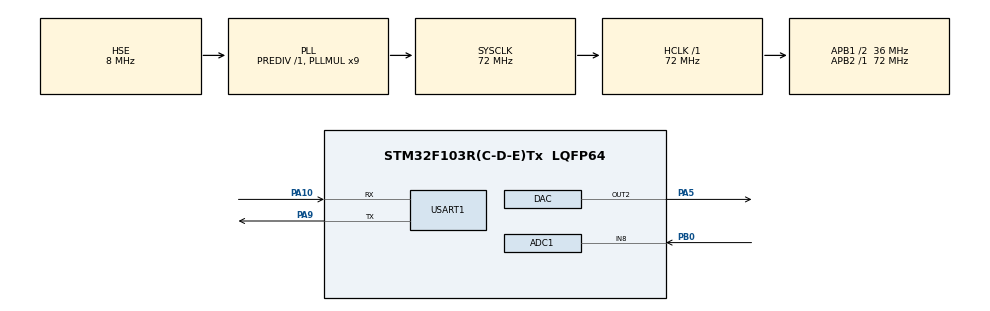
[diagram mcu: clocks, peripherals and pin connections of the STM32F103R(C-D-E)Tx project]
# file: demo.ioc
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ADC1.Channel-0\#ChannelRegularConversion=ADC_CHANNEL_8
ADC1.ContinuousConvMode=DISABLE
ADC1.NbrOfConversionFlag=1
ADC1.Rank-0\#ChannelRegularConversion=1
ADC1.SamplingTime-0\#ChannelRegularConversion=ADC_SAMPLETIME_55CYCLES_5
ADC1.master=1
DAC.DAC_Trigger2=DAC_TRIGGER_T2_TRGO
DAC.TriangleAmplitude2=DAC_TRIANGLEAMPLITUDE_4095
DAC.WaveGeneration2=TriangleWaveGeneration
Mcu.Family=STM32F1
Mcu.Name=STM32F103R(C-D-E)Tx
Mcu.Package=LQFP64
NVIC.ADC1_2_IRQn=true\:0\:0\:false\:false\:true\:true\:true
NVIC.PriorityGroup=NVIC_PRIORITYGROUP_4
NVIC.TIM6_IRQn=true\:0\:0\:false\:false\:true\:true\:true
PA10.Mode=Asynchronous
PA10.Signal=USART1_RX
PA13.Mode=Serial_Wire
PA13.Signal=SYS_JTMS-SWDIO
PA14.Mode=Serial_Wire
PA14.Signal=SYS_JTCK-SWCLK
PA5.Signal=COMP_DAC2_group
PA9.Mode=Asynchronous
PA9.Signal=USART1_TX
PB0.Signal=ADCx_IN8
PD0-OSC_IN.Mode=HSE-External-Oscillator
PD0-OSC_IN.Signal=RCC_OSC_IN
PD1-OSC_OUT.Mode=HSE-External-Oscillator
PD1-OSC_OUT.Signal=RCC_OSC_OUT
ProjectManager.HeapSize=0x200
ProjectManager.StackSize=0x400
ProjectManager.TargetToolchain=MDK-ARM V5
RCC.ADCPresc=RCC_ADCPCLK2_DIV6
RCC.AHBFreq_Value=72000000
RCC.APB1CLKDivider=RCC_HCLK_DIV2
RCC.APB1Freq_Value=36000000
RCC.APB1TimFreq_Value=72000000
RCC.APB2Freq_Value=72000000
RCC.APB2TimFreq_Value=72000000
RCC.HCLKFreq_Value=72000000
RCC.PLLMUL=RCC_PLL_MUL9
RCC.PLLSourceVirtual=RCC_PLLSOURCE_HSE
RCC.SYSCLKFreq_VALUE=72000000
RCC.SYSCLKSource=RCC_SYSCLKSOURCE_PLLCLK
RCC.USBFreq_Value=72000000
SH.ADCx_IN8.0=ADC1_IN8,IN8
SH.COMP_DAC2_group.0=DAC_OUT2,DAC_OUT2
TIM2.Period=4-1
TIM2.Prescaler=2000-1
TIM2.TIM_MasterOutputTrigger=TIM_TRGO_UPDATE
TIM6.Period=800-1
TIM6.Prescaler=2000-1
USART1.VirtualMode=VM_ASYNC
VP_TIM2_VS_ClockSourceINT.Mode=Internal
VP_TIM6_VS_ClockSourceINT.Mode=Enable_Timer
board=custom

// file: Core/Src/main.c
/* USER CODE BEGIN Header */
/**
 ******************************************************************************
 * @file           : main.c
 * @brief          : Main program body
 ******************************************************************************
 * @attention
 *
 * <h2><center>&copy; Copyright (c) 2022 STMicroelectronics.
 * All rights reserved.</center></h2>
 *
 * This software component is licensed by ST under BSD 3-Clause license,
 * the "License"; You may not use this file except in compliance with the
 * License. You may obtain a copy of the License at:
 *                        opensource.org/licenses/BSD-3-Clause
 *
 ******************************************************************************
 */
/* USER CODE END Header */

#include "main.h"
#include "adc.h"
#include "dac.h"
#include "tim.h"
#include "usart.h"
#include "gpio.h"

void SystemClock_Config(void);

/* USER CODE BEGIN 0 */
void HAL_TIM_PeriodElapsedCallback(TIM_HandleTypeDef* htim) {  // TIM
    if (htim->Instance == TIM6) HAL_ADC_Start_IT(&hadc1);
}
void HAL_ADC_ConvCpltCallback(ADC_HandleTypeDef* hadc) {  // ADC
    HAL_ADC_Stop_IT(&hadc1);
    HAL_TIM_Base_Stop_IT(&htim6);
    printf("%.2f\r\n", HAL_ADC_GetValue(&hadc1) / 4096.f * 3.3f);
    HAL_TIM_Base_Start_IT(&htim6);
}
/* USER CODE END 0 */

int main(void)
{

  /* MCU Configuration--------------------------------------------------------*/

  /* Reset of all peripherals, Initializes the Flash interface and the Systick. */
  HAL_Init();

  /* Configure the system clock */
  SystemClock_Config();

  /* Initialize all configured peripherals */
  MX_GPIO_Init();
  MX_USART1_UART_Init();
  MX_DAC_Init();
  MX_ADC1_Init();
  MX_TIM2_Init();
  MX_TIM6_Init();
  /* USER CODE BEGIN 2 */
    HAL_TIM_Base_Start_IT(&htim6);
    HAL_TIM_Base_Start(&htim2);
    HAL_DAC_Start(&hdac, DAC_CHANNEL_2);
  /* USER CODE END 2 */

  /* Infinite loop */
    while (1) {

    }
}

void SystemClock_Config(void)
{
  RCC_OscInitTypeDef RCC_OscInitStruct = {0};
  RCC_ClkInitTypeDef RCC_ClkInitStruct = {0};
  RCC_PeriphCLKInitTypeDef PeriphClkInit = {0};

  /** Initializes the CPU, AHB and APB busses clocks
  */
  RCC_OscInitStruct.OscillatorType = RCC_OSCILLATORTYPE_HSE;
  RCC_OscInitStruct.HSEState = RCC_HSE_ON;
  RCC_OscInitStruct.HSEPredivValue = RCC_HSE_PREDIV_DIV1;
  RCC_OscInitStruct.HSIState = RCC_HSI_ON;
  RCC_OscInitStruct.PLL.PLLState = RCC_PLL_ON;
  RCC_OscInitStruct.PLL.PLLSource = RCC_PLLSOURCE_HSE;
  RCC_OscInitStruct.PLL.PLLMUL = RCC_PLL_MUL9;
  if (HAL_RCC_OscConfig(&RCC_OscInitStruct) != HAL_OK)
  {
    Error_Handler();
  }
  /** Initializes the CPU, AHB and APB busses clocks
  */
  RCC_ClkInitStruct.ClockType = RCC_CLOCKTYPE_HCLK|RCC_CLOCKTYPE_SYSCLK
                              |RCC_CLOCKTYPE_PCLK1|RCC_CLOCKTYPE_PCLK2;
  RCC_ClkInitStruct.SYSCLKSource = RCC_SYSCLKSOURCE_PLLCLK;
  RCC_ClkInitStruct.AHBCLKDivider = RCC_SYSCLK_DIV1;
  RCC_ClkInitStruct.APB1CLKDivider = RCC_HCLK_DIV2;
  RCC_ClkInitStruct.APB2CLKDivider = RCC_HCLK_DIV1;

  if (HAL_RCC_ClockConfig(&RCC_ClkInitStruct, FLASH_LATENCY_2) != HAL_OK)
  {
    Error_Handler();
  }
  PeriphClkInit.PeriphClockSelection = RCC_PERIPHCLK_ADC;
  PeriphClkInit.AdcClockSelection = RCC_ADCPCLK2_DIV6;
  if (HAL_RCCEx_PeriphCLKConfig(&PeriphClkInit) != HAL_OK)
  {
    Error_Handler();
  }
}

void Error_Handler(void)
{
}

/************************ (C) COPYRIGHT STMicroelectronics *****END OF FILE****/
